# ESP32-P4 register map
Vendor: ESPRESSIF SYSTEMS (SHANGHAI) CO., LTD.; Series: ESP32 P-Series; File version: 3
CPU: RV32IMAFC r0p0, little endian, no MPU, FPU, 0 interrupt priority bits
Address unit: 32 bits
Registers are 32-bit, read-write, reset 0x0 unless marked. A register's access mark holds for its fields unless they carry their own. Offsets are from the block's base; [hi:lo] are bit positions; {n}, {i} and the like mark numbered series.

## I3C_MST_MEM — I3C_MST_MEM Peripheral
Base 0x500DA000
0x08 COMMAND_BUF_PORT
  [31:0] REG_COMMAND — Contains a Command Descriptor structure that depends on the requested transfer type. Command Descriptor structure is used to schedule the transfers to devices on I3C bus.
0x0C RESPONSE_BUF_PORT ro
  [31:0] RESPONSE — The Response Buffer can be read through this register. The response status for each Command is written into the Response Buffer by the controller if ROC (Response On Completion) bit is set or if transfer error has occurred. The response buffer can be read through this register.
0x10 RX_DATA_PORT ro
  [31:0] RX_DATA_PORT — Receive Data Port. Receive data is mapped to the Rx-data buffer and receive data is always packed in 4-byte aligned data words. If the length of data transfer is not aligned to 4-bytes boundary, then there will be extra(unused) bytes(the additional data bytes have to be ignored) at the end of the transferred data. The valid data must be identified using the DATA_LENGTH filed in the Response Descriptor.
0x14 TX_DATA_PORT
  [31:0] REG_TX_DATA_PORT — Transmit Data Port. Transmit data is mapped to the Tx-data buffer and transmit data is always packed in 4-byte aligned data words. If the length of data transfer is not aligned to 4-bytes boundary, then there will be extra(unused) bytes(the additional data bytes have to be ignored) at the end of the transferred data. The valid data must be identified using the DATA_LENGTH filed in the Response Descriptor.
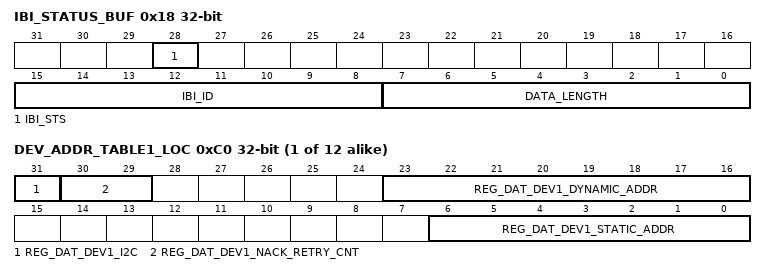
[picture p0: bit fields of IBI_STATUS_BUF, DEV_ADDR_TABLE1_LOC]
0x18 IBI_STATUS_BUF ro — In-Band Interrupt Buffer Status/Data Register. When receiving an IBI, IBI_PORT is used to both: Read the IBI Status Read the IBI Data(which is raw/opaque data)
  [28] IBI_STS — IBI received data/status. IBI Data register is mapped to the IBI Buffer. The IBI Data is always packed in4-byte aligned and put to the IBI Buffer. This register When read from, reads the data from the IBI buffer. IBI Status register when read from, returns the data from the IBI Buffer and indicates how the controller responded to incoming IBI(SIR, MR and HJ).
  [15:8] IBI_ID — IBI Identifier. The byte received after START which includes the address the R/W bit: Device address and R/W bit in case of Slave Interrupt or Master Request.
  [7:0] DATA_LENGTH — This field represents the length of data received along with IBI, in bytes.
0x40 IBI_DATA_BUF ro
  [31:0] IBI_DATA
{0xBC+4i} DEV_ADDR_TABLE{i}_LOC (i=1..12)
  [31] REG_DAT_DEV{i}_I2C — Legacy I2C device or not. This bit should be set to 1 if the device is a legacy I2C device.
  [30:29] REG_DAT_DEV{i}_NACK_RETRY_CNT — This field is used to set the Device NACK Retry count for the particular device. If the Device NACK's for the device address, the controller automatically retries the same device until this count expires. If the Slave does not ACK for the mentioned number of retries, then controller generates an error response and move to the Halt state.
  [23:16] REG_DAT_DEV{i}_DYNAMIC_ADDR — Device Dynamic Address with parity, The MSB,bit[23], should be programmed with parity of dynamic address.
  [6:0] REG_DAT_DEV{i}_STATIC_ADDR
{0xF0+0x10*i} DEV_CHAR_TABLE{i}_LOC1 ro (i=1..12)
  [31:0] DCT_DEV{i}_LOC1
{0xF4+0x10*i} DEV_CHAR_TABLE{i}_LOC2 ro (i=1..12)
  [31:0] DCT_DEV{i}_LOC2
{0xF8+0x10*i} DEV_CHAR_TABLE{i}_LOC3 ro (i=1..12)
  [31:0] DCT_DEV{i}_LOC3
{0xFC+0x10*i} DEV_CHAR_TABLE{i}_LOC4 ro (i=1..12)
  [31:0] DCT_DEV{i}_LOC4

## AXI_ICM — AXI_ICM Peripheral
Base 0x500A4000
0x00 ICM_VER_DATE — ICM version / date
  [31:0] VER_DATE
0x04 ICM_CLK_EN — ICM clock enable
  [0] CLK_EN
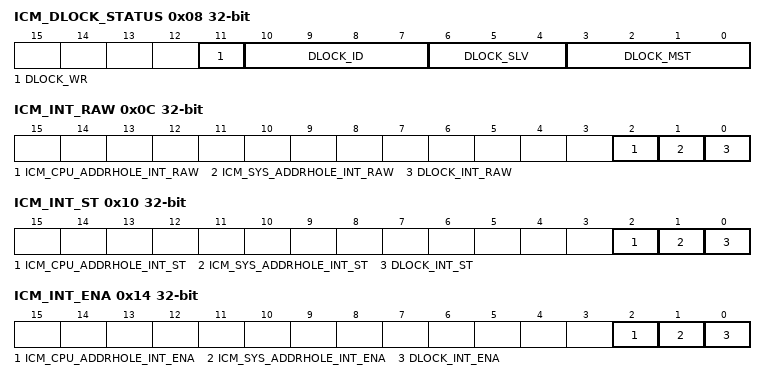
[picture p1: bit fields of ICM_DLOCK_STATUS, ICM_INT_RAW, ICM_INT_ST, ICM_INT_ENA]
0x08 ICM_DLOCK_STATUS ro — Deadlock status
  [11] DLOCK_WR, [10:7] DLOCK_ID, [6:4] DLOCK_SLV, [3:0] DLOCK_MST
0x0C ICM_INT_RAW — ICM interrupt raw
  [2] ICM_CPU_ADDRHOLE_INT_RAW, [1] ICM_SYS_ADDRHOLE_INT_RAW, [0] DLOCK_INT_RAW
0x10 ICM_INT_ST ro — ICM interrupt status
  [2] ICM_CPU_ADDRHOLE_INT_ST, [1] ICM_SYS_ADDRHOLE_INT_ST, [0] DLOCK_INT_ST
0x14 ICM_INT_ENA — ICM interrupt enable
  [2] ICM_CPU_ADDRHOLE_INT_ENA, [1] ICM_SYS_ADDRHOLE_INT_ENA, [0] DLOCK_INT_ENA
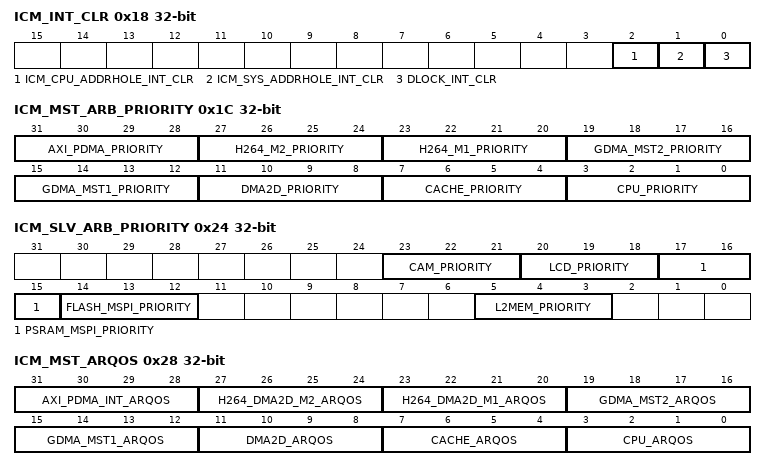
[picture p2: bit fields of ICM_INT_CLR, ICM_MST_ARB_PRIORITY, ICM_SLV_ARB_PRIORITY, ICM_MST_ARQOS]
0x18 ICM_INT_CLR wo — ICM interrupt clear
  [2] ICM_CPU_ADDRHOLE_INT_CLR, [1] ICM_SYS_ADDRHOLE_INT_CLR, [0] DLOCK_INT_CLR
0x1C ICM_MST_ARB_PRIORITY — Master arbitration priority
  [31:28] AXI_PDMA_PRIORITY, [27:24] H264_M2_PRIORITY, [23:20] H264_M1_PRIORITY, [19:16] GDMA_MST2_PRIORITY, [15:12] GDMA_MST1_PRIORITY, [11:8] DMA2D_PRIORITY, [7:4] CACHE_PRIORITY, [3:0] CPU_PRIORITY
0x24 ICM_SLV_ARB_PRIORITY — Slave arbitration priority
  [23:21] CAM_PRIORITY, [20:18] LCD_PRIORITY, [17:15] PSRAM_MSPI_PRIORITY, [14:12] FLASH_MSPI_PRIORITY, [5:3] L2MEM_PRIORITY
0x28 ICM_MST_ARQOS — Master read QoS
  [31:28] AXI_PDMA_INT_ARQOS, [27:24] H264_DMA2D_M2_ARQOS, [23:20] H264_DMA2D_M1_ARQOS, [19:16] GDMA_MST2_ARQOS, [15:12] GDMA_MST1_ARQOS, [11:8] DMA2D_ARQOS, [7:4] CACHE_ARQOS, [3:0] CPU_ARQOS
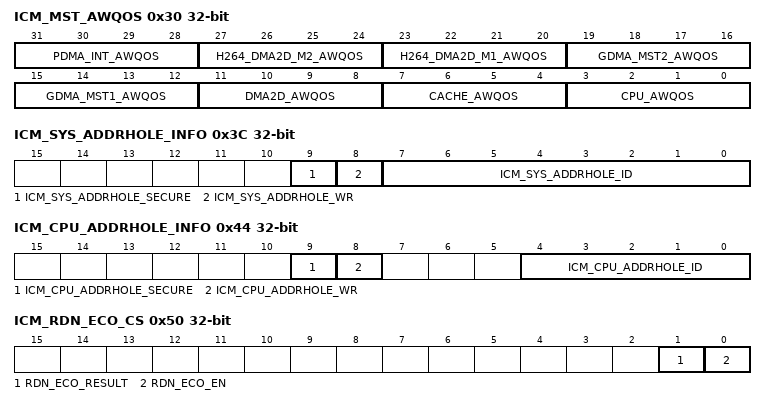
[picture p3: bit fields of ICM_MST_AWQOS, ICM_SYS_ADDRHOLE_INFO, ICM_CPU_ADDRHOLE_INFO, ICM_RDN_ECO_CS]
0x30 ICM_MST_AWQOS — Master write QoS
  [31:28] PDMA_INT_AWQOS, [27:24] H264_DMA2D_M2_AWQOS, [23:20] H264_DMA2D_M1_AWQOS, [19:16] GDMA_MST2_AWQOS, [15:12] GDMA_MST1_AWQOS, [11:8] DMA2D_AWQOS, [7:4] CACHE_AWQOS, [3:0] CPU_AWQOS
0x3C ICM_SYS_ADDRHOLE_INFO ro — SYS address hole info
  [9] ICM_SYS_ADDRHOLE_SECURE, [8] ICM_SYS_ADDRHOLE_WR, [7:0] ICM_SYS_ADDRHOLE_ID
0x40 ICM_CPU_ADDRHOLE_ADDR ro — CPU address hole address
0x44 ICM_CPU_ADDRHOLE_INFO ro — CPU address hole info
  [9] ICM_CPU_ADDRHOLE_SECURE, [8] ICM_CPU_ADDRHOLE_WR, [4:0] ICM_CPU_ADDRHOLE_ID
0x48 ICM_DLOCK_TIMEOUT — Deadlock timeout
  [12:0] DLOCK_TIMEOUT
0x50 ICM_RDN_ECO_CS — RDN ECO control/status
  [1] RDN_ECO_RESULT ro, [0] RDN_ECO_EN
0x54 ICM_RDN_ECO_LOW — RDN ECO low
  [31:0] RDN_ECO_LOW
0x58 ICM_RDN_ECO_HIGH — RDN ECO high
  [31:0] RDN_ECO_HIGH
0x38F ICM_SYS_ADDRHOLE_ADDR ro — SYS address hole address
